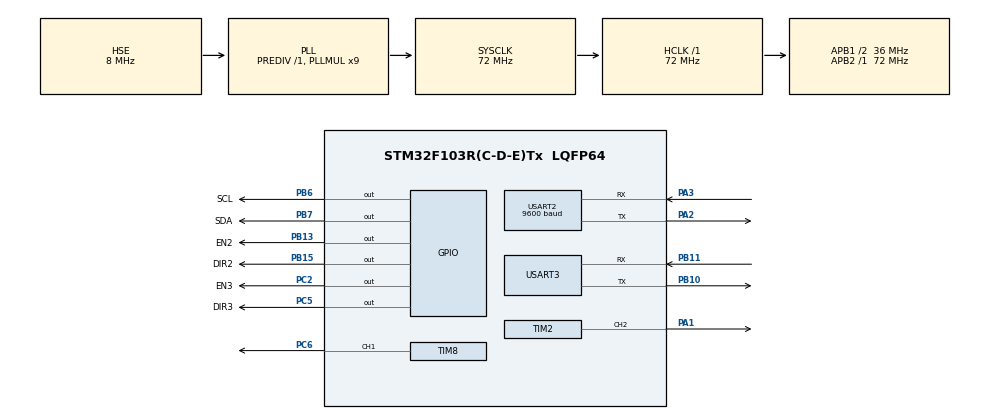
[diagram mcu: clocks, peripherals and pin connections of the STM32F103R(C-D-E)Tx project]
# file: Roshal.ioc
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Mcu.Family=STM32F1
Mcu.Name=STM32F103R(C-D-E)Tx
Mcu.Package=LQFP64
NVIC.PriorityGroup=NVIC_PRIORITYGROUP_4
NVIC.TIM2_IRQn=true\:1\:0\:true\:false\:true\:true\:true\:true
NVIC.TIM5_IRQn=true\:2\:0\:true\:false\:true\:true\:true\:true
NVIC.TIM8_UP_IRQn=true\:1\:0\:true\:false\:true\:true\:true\:true
NVIC.USART2_IRQn=true\:2\:0\:true\:false\:true\:true\:true\:true
NVIC.USART3_IRQn=true\:3\:0\:true\:false\:true\:true\:true\:true
PA1.Signal=S_TIM2_CH2
PA13.Mode=Serial_Wire
PA13.Signal=SYS_JTMS-SWDIO
PA14.Mode=Serial_Wire
PA14.Signal=SYS_JTCK-SWCLK
PA2.Mode=Asynchronous
PA2.Signal=USART2_TX
PA3.Mode=Asynchronous
PA3.Signal=USART2_RX
PB10.Mode=Asynchronous
PB10.Signal=USART3_TX
PB11.Mode=Asynchronous
PB11.Signal=USART3_RX
PB13.GPIO_Label=EN2
PB13.GPIO_ModeDefaultOutputPP=GPIO_MODE_OUTPUT_PP
PB13.GPIO_PuPd=GPIO_NOPULL
PB13.GPIO_Speed=GPIO_SPEED_FREQ_HIGH
PB13.Signal=GPIO_Output
PB15.GPIO_Label=DIR2
PB15.GPIO_ModeDefaultOutputPP=GPIO_MODE_OUTPUT_PP
PB15.GPIO_PuPd=GPIO_NOPULL
PB15.GPIO_Speed=GPIO_SPEED_FREQ_HIGH
PB15.Signal=GPIO_Output
PB6.GPIO_Label=SCL
PB6.GPIO_ModeDefaultOutputPP=GPIO_MODE_OUTPUT_OD
PB6.GPIO_PuPd=GPIO_PULLUP
PB6.GPIO_Speed=GPIO_SPEED_FREQ_MEDIUM
PB6.Signal=GPIO_Output
PB7.GPIO_Label=SDA
PB7.GPIO_ModeDefaultOutputPP=GPIO_MODE_OUTPUT_OD
PB7.GPIO_PuPd=GPIO_PULLUP
PB7.GPIO_Speed=GPIO_SPEED_FREQ_MEDIUM
PB7.Signal=GPIO_Output
PC14-OSC32_IN.Mode=LSE-External-Oscillator
PC14-OSC32_IN.Signal=RCC_OSC32_IN
PC15-OSC32_OUT.Mode=LSE-External-Oscillator
PC15-OSC32_OUT.Signal=RCC_OSC32_OUT
PC2.GPIO_Label=EN3
PC2.GPIO_ModeDefaultOutputPP=GPIO_MODE_OUTPUT_PP
PC2.GPIO_PuPd=GPIO_NOPULL
PC2.GPIO_Speed=GPIO_SPEED_FREQ_HIGH
PC2.Signal=GPIO_Output
PC5.GPIO_Label=DIR3
PC5.GPIO_ModeDefaultOutputPP=GPIO_MODE_OUTPUT_PP
PC5.GPIO_PuPd=GPIO_NOPULL
PC5.GPIO_Speed=GPIO_SPEED_FREQ_HIGH
PC5.PinState=GPIO_PIN_RESET
PC5.Signal=GPIO_Output
PC6.Signal=S_TIM8_CH1
PD0-OSC_IN.Mode=HSE-External-Oscillator
PD0-OSC_IN.Signal=RCC_OSC_IN
PD1-OSC_OUT.Mode=HSE-External-Oscillator
PD1-OSC_OUT.Signal=RCC_OSC_OUT
ProjectManager.HeapSize=0x200
ProjectManager.StackSize=0x400
ProjectManager.TargetToolchain=MDK-ARM V5.32
RCC.AHBFreq_Value=72000000
RCC.APB1CLKDivider=RCC_HCLK_DIV2
RCC.APB1Freq_Value=36000000
RCC.APB1TimFreq_Value=72000000
RCC.APB2Freq_Value=72000000
RCC.APB2TimFreq_Value=72000000
RCC.HCLKFreq_Value=72000000
RCC.PLLMUL=RCC_PLL_MUL9
RCC.PLLSourceVirtual=RCC_PLLSOURCE_HSE
RCC.SYSCLKFreq_VALUE=72000000
RCC.SYSCLKSource=RCC_SYSCLKSOURCE_PLLCLK
RCC.USBFreq_Value=72000000
SH.S_TIM2_CH2.0=TIM2_CH2,PWM Generation2 CH2
SH.S_TIM8_CH1.0=TIM8_CH1,PWM Generation1 CH1
TIM2.Channel-PWM\ Generation2\ CH2=TIM_CHANNEL_2
TIM2.OC2Preload_PWM=DISABLE
TIM2.Period=624
TIM2.Prescaler=71
TIM5.Period=399
TIM5.Prescaler=7199
TIM8.AutoReloadPreload=TIM_AUTORELOAD_PRELOAD_DISABLE
TIM8.Channel-PWM\ Generation1\ CH1=TIM_CHANNEL_1
TIM8.OC1Preload_PWM=DISABLE
TIM8.OCFastMode_PWM-PWM\ Generation1\ CH1=TIM_OCFAST_DISABLE
TIM8.Period=624
TIM8.Prescaler=71
USART2.BaudRate=9600
USART2.VirtualMode=VM_ASYNC
USART3.VirtualMode=VM_ASYNC
VP_TIM2_VS_ClockSourceINT.Mode=Internal
VP_TIM5_VS_ClockSourceINT.Mode=Internal
VP_TIM8_VS_ClockSourceINT.Mode=Internal
board=custom

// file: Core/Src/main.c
/* USER CODE BEGIN Header */
/**
  ******************************************************************************
  * @file           : main.c
  * @brief          : Main program body
  ******************************************************************************
  * @attention
  *
  * Copyright (c) 2025 STMicroelectronics.
  * All rights reserved.
  *
  * This software is licensed under terms that can be found in the LICENSE file
  * in the root directory of this software component.
  * If no LICENSE file comes with this software, it is provided AS-IS.
  *
  ******************************************************************************
  */
/* USER CODE END Header */
#include "main.h"
#include "tim.h"
#include "usart.h"
#include "gpio.h"

/* USER CODE BEGIN Includes */
#include "H_Oled.h"
#include "Usart3.h"
#include "Move.h"
#include "Conversation.h"
/* USER CODE END Includes */

void SystemClock_Config(void);

int main(void)
{

  /* MCU Configuration--------------------------------------------------------*/

  /* Reset of all peripherals, Initializes the Flash interface and the Systick. */
  HAL_Init();

  /* Configure the system clock */
  SystemClock_Config();

  /* Initialize all configured peripherals */
  MX_GPIO_Init();
  MX_TIM8_Init();
  MX_TIM2_Init();
  MX_TIM5_Init();
  MX_USART3_UART_Init();
  MX_USART2_UART_Init();
  /* USER CODE BEGIN 2 */
	OLED_Init();
	Motor_Init();
//	HAL_TIM_PWM_Start(&htim2,TIM_CHANNEL_2);
//	HAL_TIM_Base_Start_IT(&htim5);
//
//	Motor2_Enable(ENABLE);
//  Motor2_Direction(GPIO_PIN_SET);
//	Motor2_Speed(0);
  /* USER CODE END 2 */

  /* Infinite loop */
  /* USER CODE BEGIN WHILE */
  while (1)
  {
//		uint8_t speed=39;
//		Motor2_Speed(speed);
//		if(current_level==39) speed=0;
//		int tempstep2,tempspeed2;
//		int tempstep3,tempspeed3;
//
//		tempspeed2=Motor2_GetSpeed();
//		tempspeed3=Motor3_GetSpeed();
//
//		tempstep2=Motor2_GetStep();
//		tempstep3=Motor3_GetStep();

		Hx_Send();

		Left_Speed(40);
		Right_Speed(40);
//		OLED_ShowNum(1,1,tempspeed2,5);
//		OLED_ShowNum(1,7,tempspeed3,5);
//		OLED_ShowNum(2,1,tempstep2,5);
//		OLED_ShowNum(2,7,tempstep3,5);
		//Motor2_Speed(39);

    /* USER CODE END WHILE */

  }
}

void SystemClock_Config(void)
{
  RCC_OscInitTypeDef RCC_OscInitStruct = {0};
  RCC_ClkInitTypeDef RCC_ClkInitStruct = {0};

  /** Initializes the RCC Oscillators according to the specified parameters
  * in the RCC_OscInitTypeDef structure.
  */
  RCC_OscInitStruct.OscillatorType = RCC_OSCILLATORTYPE_HSE;
  RCC_OscInitStruct.HSEState = RCC_HSE_ON;
  RCC_OscInitStruct.HSEPredivValue = RCC_HSE_PREDIV_DIV1;
  RCC_OscInitStruct.HSIState = RCC_HSI_ON;
  RCC_OscInitStruct.PLL.PLLState = RCC_PLL_ON;
  RCC_OscInitStruct.PLL.PLLSource = RCC_PLLSOURCE_HSE;
  RCC_OscInitStruct.PLL.PLLMUL = RCC_PLL_MUL9;
  if (HAL_RCC_OscConfig(&RCC_OscInitStruct) != HAL_OK)
  {
    Error_Handler();
  }

  /** Initializes the CPU, AHB and APB buses clocks
  */
  RCC_ClkInitStruct.ClockType = RCC_CLOCKTYPE_HCLK|RCC_CLOCKTYPE_SYSCLK
                              |RCC_CLOCKTYPE_PCLK1|RCC_CLOCKTYPE_PCLK2;
  RCC_ClkInitStruct.SYSCLKSource = RCC_SYSCLKSOURCE_PLLCLK;
  RCC_ClkInitStruct.AHBCLKDivider = RCC_SYSCLK_DIV1;
  RCC_ClkInitStruct.APB1CLKDivider = RCC_HCLK_DIV2;
  RCC_ClkInitStruct.APB2CLKDivider = RCC_HCLK_DIV1;

  if (HAL_RCC_ClockConfig(&RCC_ClkInitStruct, FLASH_LATENCY_2) != HAL_OK)
  {
    Error_Handler();
  }
}

void Error_Handler(void)
{
  __disable_irq();
  while (1)
  {
  }
}
